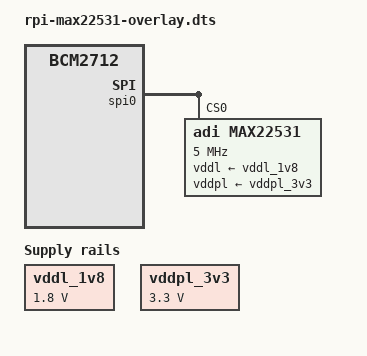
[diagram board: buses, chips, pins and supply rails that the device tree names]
// SPDX-License-Identifier: (GPL-2.0+)
/*
 * Device Tree Overlay for MAX22531 
 */

/dts-v1/;
/plugin/;

/ {
	compatible = "brcm,bcm2835", "brcm,bcm2711", "brcm,bcm2712";

	vddl_1v8: fixedregulator@0 {
		compatible = "regulator-fixed";
		regulator-name = "Power Input for the Logic-Side";
		regulator-min-microvolt = <1800000>;
		regulator-max-microvolt = <1800000>;
		regulator-boot-on;
		regulator-always-on;
	};

	vddpl_3v3: fixedregulator@1 {
		compatible = "regulator-fixed";
		regulator-name = "Power Input for the Isolated DC-DC Converter";
		regulator-min-microvolt = <3300000>;
		regulator-max-microvolt = <3300000>;
		regulator-boot-on;
		regulator-always-on;
	};
};

&spi0 {
	status = "okay";

	max22531@0 {
		compatible = "adi,max22531";
		reg = <0>;	/* Using CS0 on spi0 */
		spi-max-frequency = <5000000>;
		vddl-supply = <&vddl_1v8>;
		vddpl-supply = <&vddpl_3v3>;
	};
};
